# SAMA7G54D4G device description
Architecture: CORTEX-A7; Family: SAMA; Series: SAMA7G
Registers are 32-bit, read-write, reset 0x0 unless marked. A register's access mark holds for its fields unless they carry their own. Offsets are from the block's base; [hi:lo] are bit positions; lines under a group give offsets from that group; {n}, {i} and the like mark numbered series.

## SFRBU — Special Function Register Backup
Instances: SFRBU 0xE0008000
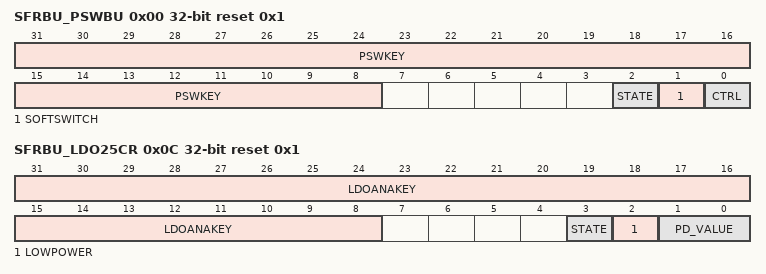
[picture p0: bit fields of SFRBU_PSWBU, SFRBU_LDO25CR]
0x00 SFRBU_PSWBU reset 0x1 — Power Switch BU Control
  [31:8] PSWKEY — Specific Value Mandatory to Allow Writing of Other Register Bits (Write-only)
    0x4BD20C=PASSWD (Writing any other value in this field aborts the write operation in the SFRBU_PSWBU register. Always reads as 0.)
  [2] STATE — Power Switch BU State (Read-only)
    0=VBAT (LDO BU Supply source is VBAT.); 1=VDDIN33 (LDO BU Supply source is VDDIN33.)
  [1] SOFTSWITCH — Power Switch BU Source Selection
    0=VBAT (LDO Supply source is VBAT.); 1=VDDIN33 (LDO Supply source is VDDIN33.)
  [0] CTRL — Power Switch BU Control
    0=HARD (Power Switch BU is controlled by hardware (SOFTSWITCH bit has no action).); 1=SOFT (Power Switch BU is controlled by software (SOFTSWITCH bit has an action).)
0x0C SFRBU_LDO25CR reset 0x1 — VDDANAout LDO Pulldown Value
  [31:8] LDOANAKEY — Specific value mandatory to allow writing of other register bits
    0x3B6E18=PASSWD (Writing any other value in this field aborts the write operation in the SFRBU_LDO25CR register. Always reads as 0.)
  [3] STATE — LDOANA Switch On/Off Control
    0=ON (Switches LDOANA on.); 1=OFF (Switches LDOANA off.)
  [2] LOWPOWER — LDOANA Low-Power Mode Control
    0=NOT_SET (Switches LDOANA Low-power mode off.); 1=SET (Switches LDOANA Low-power mode on.)
  [1:0] PD_VALUE — LDOANA Pull-down Value
    0=NONE (No pull-down plugged on LDO output when off.); 1=500_OHMS (500 Ohms pull-down plugged on LDO output when off.); 2=200_OHMS (200 Ohms pull-down plugged on LDO output when off.); 3=100_OHMS (100 Ohms pull-down plugged on LDO output when off.)
0x10 SFRBU_DDRPWR — DDR Power Control
  [0] STATE — DDR Power Mode State
    0=ON (DDR Power mode is on.); 1=OFF (DDR Power mode is off.)

## SYSCWP — External Interrupt Controller
Instances: SYSCWP 0xE001D0DC
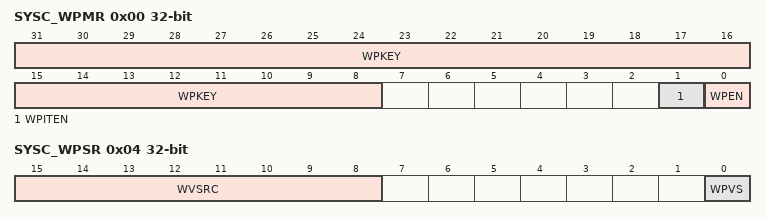
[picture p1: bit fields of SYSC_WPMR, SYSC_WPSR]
0x00 SYSC_WPMR — Write Protection Mode Register
  [31:8] WPKEY — Write Protection Key
    0x535943=PASSWD (Writing any other value in this field aborts the write operation of the WPEN and WPITEN bits. Always reads as 0.)
  [1] WPITEN — Write Protection RTC Interrupt Enable
    0=Disables the write protection of the RTC_IER/RTC_IDR configuration registers if WPKEY corresponds to 0x535943 ("SYC" in ASCII); 1=Enables the write protection of the RTC_IER/RTC_IDR configuration registers if WPKEY corresponds to 0x535943 ("SYC" in ASCII)
  [0] WPEN — Write Protection Enable
    0=Disables the write protection of the configuration registers if WPKEY corresponds to 0x535943 ("SYC" in ASCII); 1=Enables the write protection of the configuration registers if WPKEY corresponds to 0x535943 ("SYC" in ASCII)
0x04 SYSC_WPSR ro — Write Protection Status Register
  [15:8] WVSRC — Write Violation Source
  [0] WPVS — Write Protection Register Violation Status
    0=No write protection violation has occurred since the last read of SYSC_WPSR; 1=A write protection violation has occurred since the last read of SYSC_WPSR. The associated violation is reported into field WVSRC.

## TZAESBASC — AES Bridge Address Space Controller
Instances: TZAESBASC 0xE2000000
{0x0+8i} TZAESBASC_RID[{i}] (i=0..7) group
  0x00 TZAESBASC_RBAR — Region Base Address
    [31:0] BASE
  0x04 TZAESBASC_RTAR — Region Top Address
    [31:0] TOP
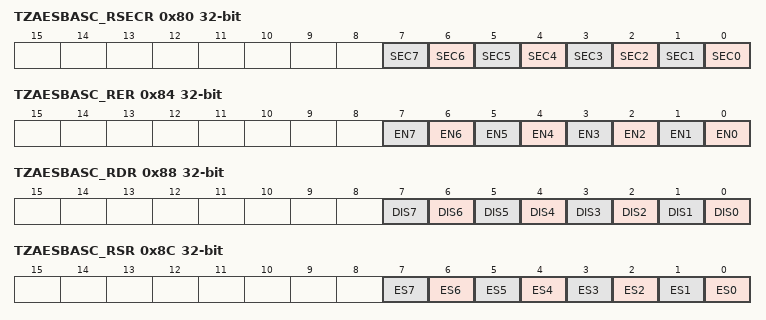
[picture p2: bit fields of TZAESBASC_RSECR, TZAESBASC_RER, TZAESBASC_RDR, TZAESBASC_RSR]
0x80 TZAESBASC_RSECR — Region Security
  [all] fields
    0=Region x is secure; 1=Region x is non-secure
  [n] SEC{n} (n=0..7) — Region {n} Security
0x84 TZAESBASC_RER wo reset not defined — Region Enable
  [all] fields
    0=No effect; 1=Enables the corresponding region
  [n] EN{n} (n=0..7) — Region {n} Enable
0x88 TZAESBASC_RDR wo reset not defined (atomic clear of TZAESBASC_RSR) — Region Disable
  [all] fields
    0=No effect; 1=Disables the corresponding region
  [n] DIS{n} (n=0..7) — Region {n} Disable
0x8C TZAESBASC_RSR ro — Region Status
  [all] fields
    0=The corresponding region is disabled; 1=The corresponding region is enabled
  [n] ES{n} (n=0..7) — Region {n} Enable Status
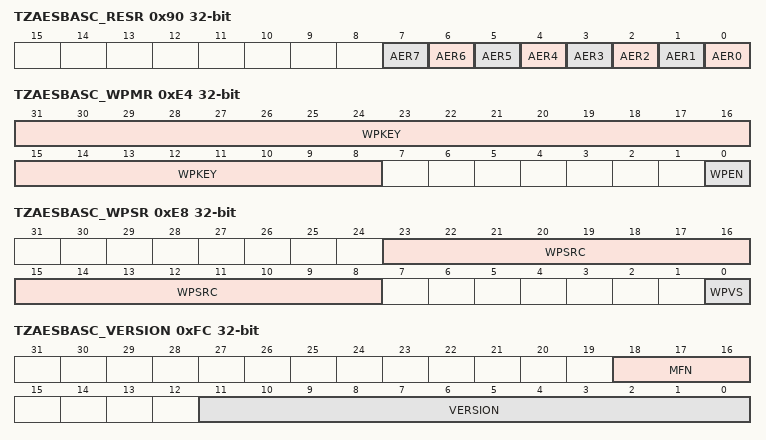
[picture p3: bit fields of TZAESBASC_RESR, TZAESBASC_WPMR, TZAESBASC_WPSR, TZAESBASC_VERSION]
0x90 TZAESBASC_RESR ro — Region Error Status
  [all] fields
    0=No region x address error has occurred; 1=A region x address error has occurred since the last read of the Region Error Status register
  [n] AER{n} (n=0..7) — Region {n} Address Error
0x94 TZAESBASC_RSSR ro (atomic set of TZAESBASC_RSR) — Region Synchronization Status
  [0] SYNC
    0=Synchronization of the region configuration is done; 1=A region configuration is in progress
0xE4 TZAESBASC_WPMR — Write Protection Mode Register
  [31:8] WPKEY — Write Protection Key
    0x415343=PASSWD (Writing any other value in this field aborts the write operation of the WPEN bit. Always reads at 0.)
  [0] WPEN — Write Protection Enable
    0=Disables the write protection if WPKEY corresponds to 0x415343 ("ASC" in ASCII); 1=Enables the write protection. All accesses to configuration registers are canceled and generate an error in the TZAESBASC_WPSR register.
0xE8 TZAESBASC_WPSR ro — Write Protection Status Register
  [23:8] WPSRC — Write Protection Source
  [0] WPVS — Write Protection Violation Status
    0=No write protection violation has occurred since the last read of IP_Acronym_WPSR; 1=A write protection violation has occurred since the last read of IP_Acronym_WPSR. If this violation is an unauthorized attempt to write a protected register, the associated violation is reported into field WPSRC.
0xFC TZAESBASC_VERSION ro reset not defined — Version Register
  [18:16] MFN — Metal Fix Number
  [11:0] VERSION — Version of the Hardware Module

## TZPM — System Interconnect and Security
Instances: TZPM 0xE0010000
0x04 TZPM_KEY — TrustZone Peripheral Manager Key
  [31:0] TZPMKEY — Key preventing TZPM_PIDRx registers to be modified unintentionally by software
    0x12AC4B5D=PASSWD (Writing any other value in this field aborts the write operation of the TZPM_PIDRx Registers. Always reads as 0.)
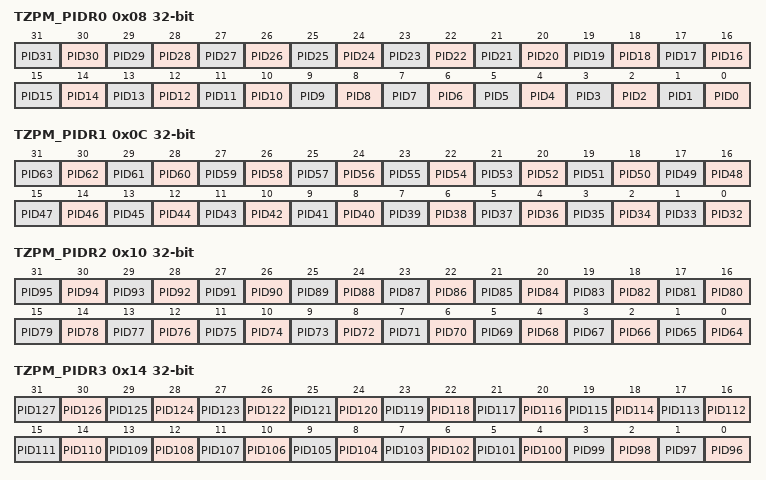
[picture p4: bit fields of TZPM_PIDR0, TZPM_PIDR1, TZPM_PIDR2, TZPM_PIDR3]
0x08 TZPM_PIDR0 — TrustZone Peripheral Manager Peripheral ID Register 0
  [all] fields
    0=Secure Accesses only; 1=Non Secure Accesses are allowed
  [n] PID{n} (n=0..31) — Peripheral ID {n} Security
0x0C TZPM_PIDR1 — TrustZone Peripheral Manager Peripheral ID Register 1
  [all] fields
    0=Secure Accesses only; 1=Non Secure Accesses are allowed
  [n-32] PID{n} (n=32..63) — Peripheral ID {n} Security
0x10 TZPM_PIDR2 — TrustZone Peripheral Manager Peripheral ID Register 2
  [all] fields
    0=Secure Accesses only; 1=Non Secure Accesses are allowed
  [n-64] PID{n} (n=64..95) — Peripheral ID {n} Security
0x14 TZPM_PIDR3 — TrustZone Peripheral Manager Peripheral ID Register 3
  [all] fields
    0=Secure Accesses only; 1=Non Secure Accesses are allowed
  [n-96] PID{n} (n=96..127) — Peripheral ID {n} Security
